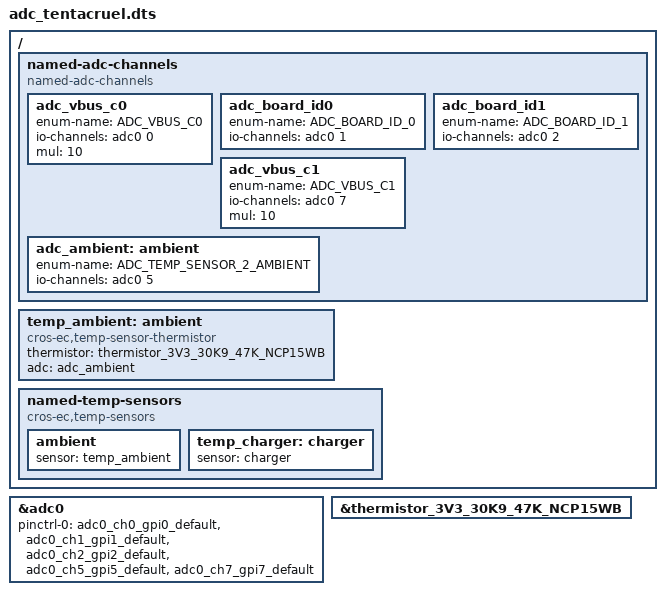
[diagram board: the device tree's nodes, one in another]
/* Copyright 2022 The ChromiumOS Authors
 * Use of this source code is governed by a BSD-style license that can be
 * found in the LICENSE file.
 */

#include <cros/thermistor/thermistor.dtsi>

/ {
	named-adc-channels {
		compatible = "named-adc-channels";
		adc_vbus_c0 {
			enum-name = "ADC_VBUS_C0";
			io-channels = <&adc0 0>;
			mul = <10>;
		};
		adc_board_id0 {
			enum-name = "ADC_BOARD_ID_0";
			io-channels = <&adc0 1>;
		};
		adc_board_id1 {
			enum-name = "ADC_BOARD_ID_1";
			io-channels = <&adc0 2>;
		};
		adc_vbus_c1 {
			enum-name = "ADC_VBUS_C1";
			io-channels = <&adc0 7>;
			mul = <10>;
		};
		adc_ambient: ambient {
			enum-name = "ADC_TEMP_SENSOR_2_AMBIENT";
			io-channels = <&adc0 5>;
		};
	};
};

&adc0 {
	status = "okay";
	pinctrl-0 = <&adc0_ch0_gpi0_default
		     &adc0_ch1_gpi1_default
		     &adc0_ch2_gpi2_default
		     &adc0_ch5_gpi5_default
		     &adc0_ch7_gpi7_default>;
	pinctrl-names = "default";
};

/ {
	temp_ambient: ambient {
		compatible = "cros-ec,temp-sensor-thermistor";
		thermistor = <&thermistor_3V3_30K9_47K_NCP15WB>;
		adc = <&adc_ambient>;
	};

	named-temp-sensors {
		compatible = "cros-ec,temp-sensors";
		ambient {
			sensor = <&temp_ambient>;
		};
		temp_charger: charger {
			sensor = <&charger>;
		};
	};
};

&thermistor_3V3_30K9_47K_NCP15WB {
	status = "okay";
};
